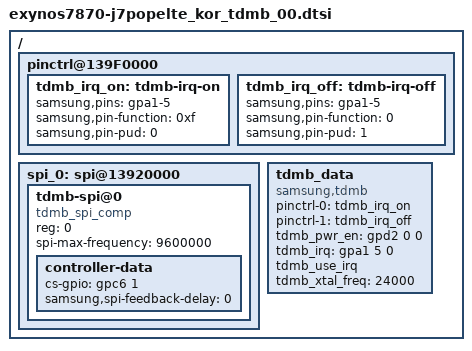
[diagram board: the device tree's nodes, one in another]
/*
 * SAMSUNG UNIVERSAL7870 board device tree source
 *
 * Copyright (c) 2013 Samsung Electronics Co., Ltd.
 *		http://www.samsung.com
 *
 * This program is free software; you can redistribute it and/or modify
 * it under the terms of the GNU General Public License version 2 as
 * published by the Free Software Foundation.
*/

/{
	pinctrl@139F0000 {
		tdmb_irq_on: tdmb-irq-on {
			samsung,pins = "gpa1-5";
			samsung,pin-function = <0xf>; /* EXT_INT */
			samsung,pin-pud = <0>;	/* PULL NONE */
		};
		tdmb_irq_off: tdmb-irq-off {
			samsung,pins = "gpa1-5";
			samsung,pin-function = <0>; /* INPUT */
			samsung,pin-pud = <1>;	/* PULL DOWN */
		};
	};

	spi_0: spi@13920000 {
		status = "ok";

		tdmb-spi@0 {
			compatible = "tdmb_spi_comp";
			reg = <0>;
			spi-max-frequency = <9600000>;
			controller-data {
				cs-gpio = <&gpc6 1 0>;
				samsung,spi-feedback-delay = <0>;
			};
		};
	};

	tdmb_data {
		compatible = "samsung,tdmb";
		pinctrl-names = "tdmb_on", "tdmb_off";
		pinctrl-0 = <&tdmb_irq_on>;
		pinctrl-1 = <&tdmb_irq_off>;
		tdmb_pwr_en = <&gpd2 0 0>;
		tdmb_irq = <&gpa1 5 0>;
		/* tdmb_fm_ant_sel = <&gpa1 3 0>; */
		tdmb_use_irq;
		tdmb_xtal_freq = <24000>;
	};

};
